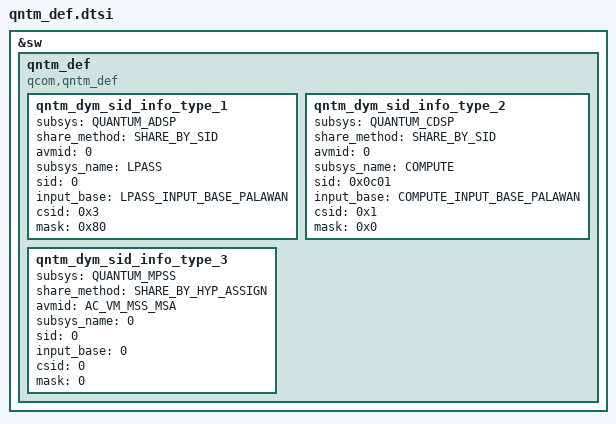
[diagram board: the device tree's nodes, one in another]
/**

This is the configuration file for Quantum sid mapping 

Copyright (c) 2023-2024 by Qualcomm Technologies, Inc.  All Rights Reserved.
Confidential and Proprietary - Qualcomm Technologies, Inc.

**/

#include <qntm_defines_common.h>
#include <qntm_defines.h>

&sw {
 qntm_def {
  
  compatible = "qcom,qntm_def";
  
  qntm_dym_sid_info_type_1 {
    subsys                = <QUANTUM_ADSP>;
    share_method          = <SHARE_BY_SID>;
    avmid                 = <0>;
    subsys_name           = "LPASS";
    sid                   = <0>;
    input_base            = <LPASS_INPUT_BASE_PALAWAN>;
    csid                  = <0x3>;
    mask                  = <0x80>;
  };
  qntm_dym_sid_info_type_2 {
    subsys                = <QUANTUM_CDSP>;
    share_method          = <SHARE_BY_SID>;
    avmid                 = <0>;
    subsys_name           = "COMPUTE";
    sid                   = <0x0c01>;
    input_base            = <COMPUTE_INPUT_BASE_PALAWAN>;
    csid                  = <0x1>;
    mask                  = <0x0>;
  };
  qntm_dym_sid_info_type_3 {
    subsys                = <QUANTUM_MPSS>;
    share_method          = <SHARE_BY_HYP_ASSIGN>;
    avmid                 = <AC_VM_MSS_MSA>;
    subsys_name           = <0>;
    sid                   = <0>;
    input_base             = <0>;
    csid                  = <0>;
    mask                  = <0>;
  };
 };
};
